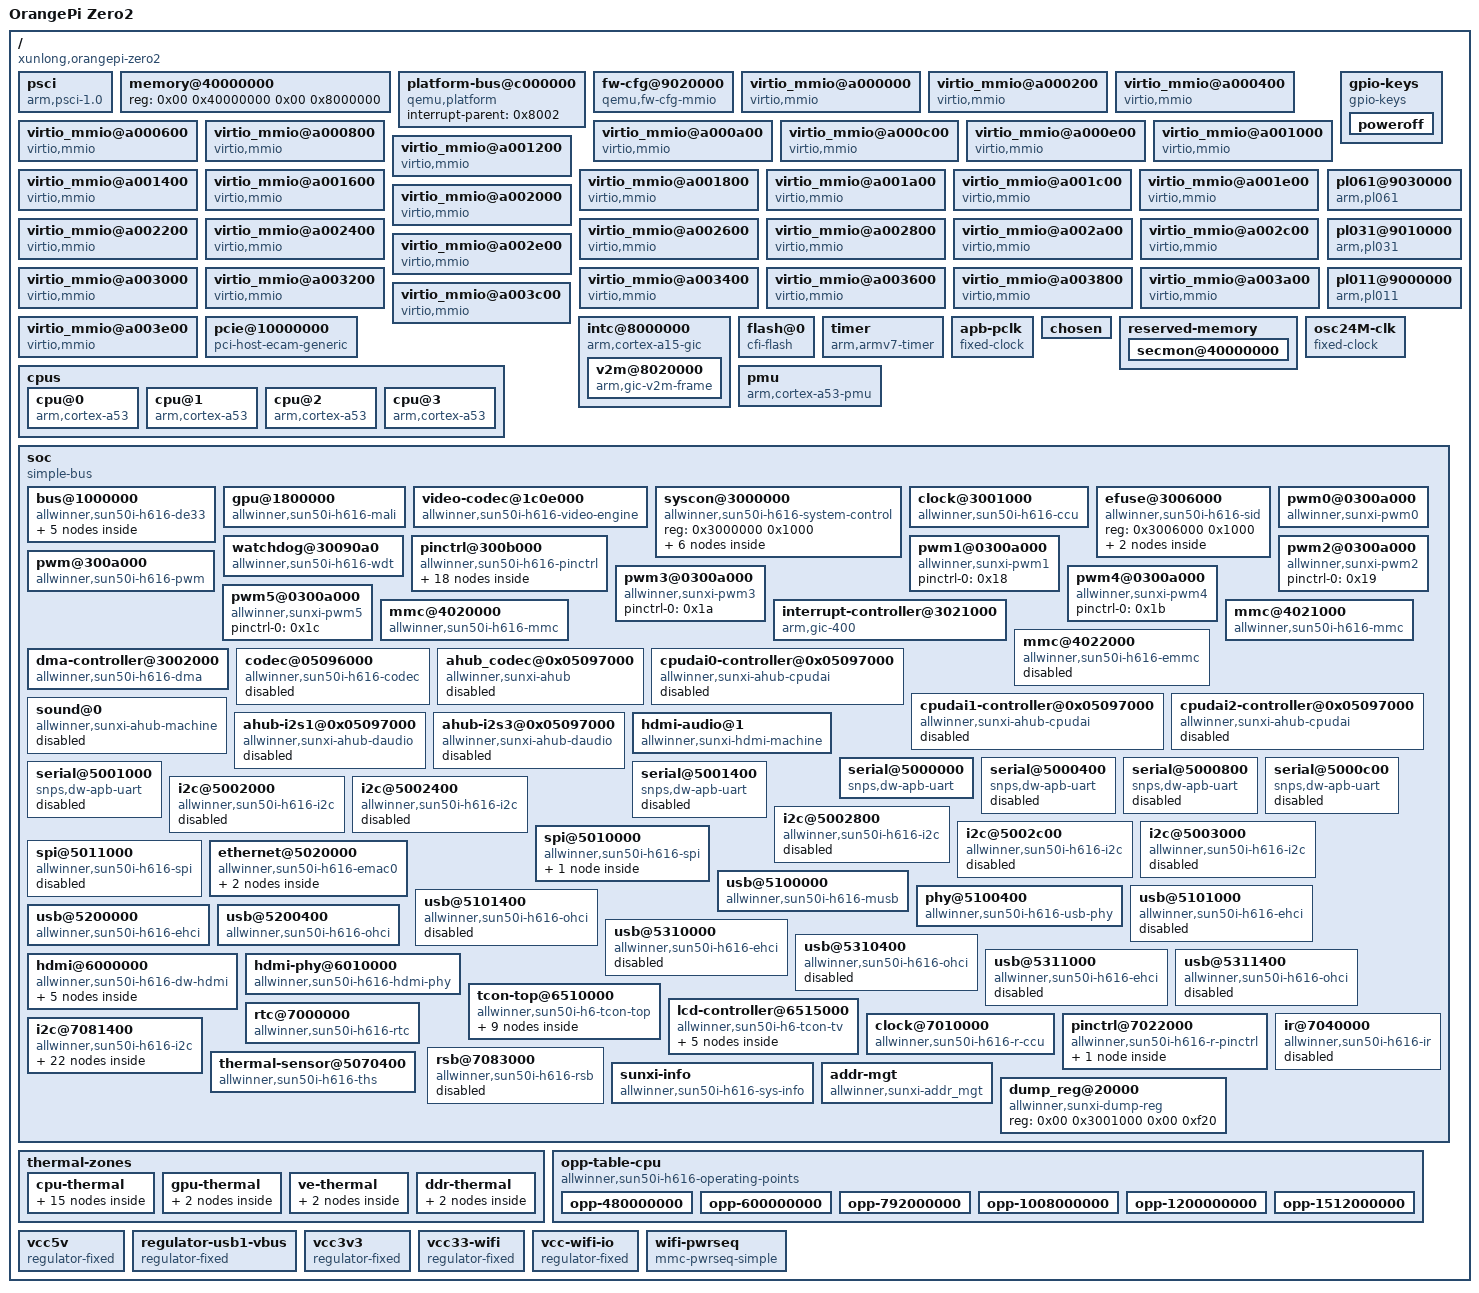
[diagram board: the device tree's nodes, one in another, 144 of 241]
/dts-v1/;

/ {
	#size-cells = <0x02>;
	#address-cells = <0x02>;

	model = "OrangePi Zero2";
	compatible = "xunlong,orangepi-zero2\0allwinner,sun50i-h616";

// qemu specific
	interrupt-parent = <0x8002>;

	psci {
		migrate = <0x84000005>;
		cpu_on = <0x84000003>;
		cpu_off = <0x84000002>;
		cpu_suspend = <0x84000001>;
		method = "hvc";
		compatible = "arm,psci-1.0\0arm,psci-0.2\0arm,psci";
	};

	memory@40000000 {
		reg = <0x00 0x40000000 0x00 0x8000000>;
		device_type = "memory";
	};

	platform-bus@c000000 {
		interrupt-parent = <0x8002>;
		ranges = <0x00 0x00 0xc000000 0x2000000>;
		#address-cells = <0x01>;
		#size-cells = <0x01>;
		compatible = "qemu,platform\0simple-bus";
	};

	fw-cfg@9020000 {
		dma-coherent;
		reg = <0x00 0x9020000 0x00 0x18>;
		compatible = "qemu,fw-cfg-mmio";
	};

	virtio_mmio@a000000 {
		dma-coherent;
		interrupts = <0x00 0x10 0x01>;
		reg = <0x00 0xa000000 0x00 0x200>;
		compatible = "virtio,mmio";
	};

	virtio_mmio@a000200 {
		dma-coherent;
		interrupts = <0x00 0x11 0x01>;
		reg = <0x00 0xa000200 0x00 0x200>;
		compatible = "virtio,mmio";
	};

	virtio_mmio@a000400 {
		dma-coherent;
		interrupts = <0x00 0x12 0x01>;
		reg = <0x00 0xa000400 0x00 0x200>;
		compatible = "virtio,mmio";
	};

	virtio_mmio@a000600 {
		dma-coherent;
		interrupts = <0x00 0x13 0x01>;
		reg = <0x00 0xa000600 0x00 0x200>;
		compatible = "virtio,mmio";
	};

	virtio_mmio@a000800 {
		dma-coherent;
		interrupts = <0x00 0x14 0x01>;
		reg = <0x00 0xa000800 0x00 0x200>;
		compatible = "virtio,mmio";
	};

	virtio_mmio@a000a00 {
		dma-coherent;
		interrupts = <0x00 0x15 0x01>;
		reg = <0x00 0xa000a00 0x00 0x200>;
		compatible = "virtio,mmio";
	};

	virtio_mmio@a000c00 {
		dma-coherent;
		interrupts = <0x00 0x16 0x01>;
		reg = <0x00 0xa000c00 0x00 0x200>;
		compatible = "virtio,mmio";
	};

	virtio_mmio@a000e00 {
		dma-coherent;
		interrupts = <0x00 0x17 0x01>;
		reg = <0x00 0xa000e00 0x00 0x200>;
		compatible = "virtio,mmio";
	};

	virtio_mmio@a001000 {
		dma-coherent;
		interrupts = <0x00 0x18 0x01>;
		reg = <0x00 0xa001000 0x00 0x200>;
		compatible = "virtio,mmio";
	};

	virtio_mmio@a001200 {
		dma-coherent;
		interrupts = <0x00 0x19 0x01>;
		reg = <0x00 0xa001200 0x00 0x200>;
		compatible = "virtio,mmio";
	};

	virtio_mmio@a001400 {
		dma-coherent;
		interrupts = <0x00 0x1a 0x01>;
		reg = <0x00 0xa001400 0x00 0x200>;
		compatible = "virtio,mmio";
	};

	virtio_mmio@a001600 {
		dma-coherent;
		interrupts = <0x00 0x1b 0x01>;
		reg = <0x00 0xa001600 0x00 0x200>;
		compatible = "virtio,mmio";
	};

	virtio_mmio@a001800 {
		dma-coherent;
		interrupts = <0x00 0x1c 0x01>;
		reg = <0x00 0xa001800 0x00 0x200>;
		compatible = "virtio,mmio";
	};

	virtio_mmio@a001a00 {
		dma-coherent;
		interrupts = <0x00 0x1d 0x01>;
		reg = <0x00 0xa001a00 0x00 0x200>;
		compatible = "virtio,mmio";
	};

	virtio_mmio@a001c00 {
		dma-coherent;
		interrupts = <0x00 0x1e 0x01>;
		reg = <0x00 0xa001c00 0x00 0x200>;
		compatible = "virtio,mmio";
	};

	virtio_mmio@a001e00 {
		dma-coherent;
		interrupts = <0x00 0x1f 0x01>;
		reg = <0x00 0xa001e00 0x00 0x200>;
		compatible = "virtio,mmio";
	};

	virtio_mmio@a002000 {
		dma-coherent;
		interrupts = <0x00 0x20 0x01>;
		reg = <0x00 0xa002000 0x00 0x200>;
		compatible = "virtio,mmio";
	};

	virtio_mmio@a002200 {
		dma-coherent;
		interrupts = <0x00 0x21 0x01>;
		reg = <0x00 0xa002200 0x00 0x200>;
		compatible = "virtio,mmio";
	};

	virtio_mmio@a002400 {
		dma-coherent;
		interrupts = <0x00 0x22 0x01>;
		reg = <0x00 0xa002400 0x00 0x200>;
		compatible = "virtio,mmio";
	};

	virtio_mmio@a002600 {
		dma-coherent;
		interrupts = <0x00 0x23 0x01>;
		reg = <0x00 0xa002600 0x00 0x200>;
		compatible = "virtio,mmio";
	};

	virtio_mmio@a002800 {
		dma-coherent;
		interrupts = <0x00 0x24 0x01>;
		reg = <0x00 0xa002800 0x00 0x200>;
		compatible = "virtio,mmio";
	};

	virtio_mmio@a002a00 {
		dma-coherent;
		interrupts = <0x00 0x25 0x01>;
		reg = <0x00 0xa002a00 0x00 0x200>;
		compatible = "virtio,mmio";
	};

	virtio_mmio@a002c00 {
		dma-coherent;
		interrupts = <0x00 0x26 0x01>;
		reg = <0x00 0xa002c00 0x00 0x200>;
		compatible = "virtio,mmio";
	};

	virtio_mmio@a002e00 {
		dma-coherent;
		interrupts = <0x00 0x27 0x01>;
		reg = <0x00 0xa002e00 0x00 0x200>;
		compatible = "virtio,mmio";
	};

	virtio_mmio@a003000 {
		dma-coherent;
		interrupts = <0x00 0x28 0x01>;
		reg = <0x00 0xa003000 0x00 0x200>;
		compatible = "virtio,mmio";
	};

	virtio_mmio@a003200 {
		dma-coherent;
		interrupts = <0x00 0x29 0x01>;
		reg = <0x00 0xa003200 0x00 0x200>;
		compatible = "virtio,mmio";
	};

	virtio_mmio@a003400 {
		dma-coherent;
		interrupts = <0x00 0x2a 0x01>;
		reg = <0x00 0xa003400 0x00 0x200>;
		compatible = "virtio,mmio";
	};

	virtio_mmio@a003600 {
		dma-coherent;
		interrupts = <0x00 0x2b 0x01>;
		reg = <0x00 0xa003600 0x00 0x200>;
		compatible = "virtio,mmio";
	};

	virtio_mmio@a003800 {
		dma-coherent;
		interrupts = <0x00 0x2c 0x01>;
		reg = <0x00 0xa003800 0x00 0x200>;
		compatible = "virtio,mmio";
	};

	virtio_mmio@a003a00 {
		dma-coherent;
		interrupts = <0x00 0x2d 0x01>;
		reg = <0x00 0xa003a00 0x00 0x200>;
		compatible = "virtio,mmio";
	};

	virtio_mmio@a003c00 {
		dma-coherent;
		interrupts = <0x00 0x2e 0x01>;
		reg = <0x00 0xa003c00 0x00 0x200>;
		compatible = "virtio,mmio";
	};

	virtio_mmio@a003e00 {
		dma-coherent;
		interrupts = <0x00 0x2f 0x01>;
		reg = <0x00 0xa003e00 0x00 0x200>;
		compatible = "virtio,mmio";
	};

	gpio-keys {
		compatible = "gpio-keys";

		poweroff {
			gpios = <0x8004 0x03 0x00>;
			linux,code = <0x74>;
			label = "GPIO Key Poweroff";
		};
	};

	pl061@9030000 {
		phandle = <0x8004>;
		clock-names = "apb_pclk";
		clocks = <0x8000>;
		interrupts = <0x00 0x07 0x04>;
		gpio-controller;
		#gpio-cells = <0x02>;
		compatible = "arm,pl061\0arm,primecell";
		reg = <0x00 0x9030000 0x00 0x1000>;
	};

	pcie@10000000 {
		interrupt-map-mask = <0x1800 0x00 0x00 0x07>;
		interrupt-map = <0x00 0x00 0x00 0x01 0x8002 0x00 0x00 0x00 0x03 0x04 0x00 0x00 0x00 0x02 0x8002 0x00 0x00 0x00 0x04 0x04 0x00 0x00 0x00 0x03 0x8002 0x00 0x00 0x00 0x05 0x04 0x00 0x00 0x00 0x04 0x8002 0x00 0x00 0x00 0x06 0x04 0x800 0x00 0x00 0x01 0x8002 0x00 0x00 0x00 0x04 0x04 0x800 0x00 0x00 0x02 0x8002 0x00 0x00 0x00 0x05 0x04 0x800 0x00 0x00 0x03 0x8002 0x00 0x00 0x00 0x06 0x04 0x800 0x00 0x00 0x04 0x8002 0x00 0x00 0x00 0x03 0x04 0x1000 0x00 0x00 0x01 0x8002 0x00 0x00 0x00 0x05 0x04 0x1000 0x00 0x00 0x02 0x8002 0x00 0x00 0x00 0x06 0x04 0x1000 0x00 0x00 0x03 0x8002 0x00 0x00 0x00 0x03 0x04 0x1000 0x00 0x00 0x04 0x8002 0x00 0x00 0x00 0x04 0x04 0x1800 0x00 0x00 0x01 0x8002 0x00 0x00 0x00 0x06 0x04 0x1800 0x00 0x00 0x02 0x8002 0x00 0x00 0x00 0x03 0x04 0x1800 0x00 0x00 0x03 0x8002 0x00 0x00 0x00 0x04 0x04 0x1800 0x00 0x00 0x04 0x8002 0x00 0x00 0x00 0x05 0x04>;
		#interrupt-cells = <0x01>;
		ranges = <0x1000000 0x00 0x00 0x00 0x3eff0000 0x00 0x10000 0x2000000 0x00 0x10000000 0x00 0x10000000 0x00 0x2eff0000 0x3000000 0x80 0x00 0x80 0x00 0x80 0x00>;
		reg = <0x40 0x10000000 0x00 0x10000000>;
		msi-map = <0x00 0x8003 0x00 0x10000>;
		dma-coherent;
		bus-range = <0x00 0xff>;
		linux,pci-domain = <0x00>;
		#size-cells = <0x02>;
		#address-cells = <0x03>;
		device_type = "pci";
		compatible = "pci-host-ecam-generic";
	};

	pl031@9010000 {
		clock-names = "apb_pclk";
		clocks = <0x8000>;
		interrupts = <0x00 0x02 0x04>;
		reg = <0x00 0x9010000 0x00 0x1000>;
		compatible = "arm,pl031\0arm,primecell";
	};

	pl011@9000000 {
		clock-names = "uartclk\0apb_pclk";
		clocks = <0x8000 0x8000>;
		interrupts = <0x00 0x01 0x04>;
		reg = <0x00 0x9000000 0x00 0x1000>;
		compatible = "arm,pl011\0arm,primecell";
	};

	intc@8000000 {
		phandle = <0x8002>;
		reg = <0x00 0x8000000 0x00 0x10000 0x00 0x8010000 0x00 0x10000>;
		compatible = "arm,cortex-a15-gic";
		ranges;
		#size-cells = <0x02>;
		#address-cells = <0x02>;
		interrupt-controller;
		#interrupt-cells = <0x03>;

		v2m@8020000 {
			phandle = <0x8003>;
			reg = <0x00 0x8020000 0x00 0x1000>;
			msi-controller;
			compatible = "arm,gic-v2m-frame";
		};
	};

	flash@0 {
		bank-width = <0x04>;
		reg = <0x00 0x00 0x00 0x4000000 0x00 0x4000000 0x00 0x4000000>;
		compatible = "cfi-flash";
	};

	timer {
		interrupts = <0x01 0x0d 0x104 0x01 0x0e 0x104 0x01 0x0b 0x104 0x01 0x0a 0x104>;
		always-on;
		compatible = "arm,armv7-timer";
	};

	apb-pclk {
		phandle = <0x8000>;
		clock-output-names = "clk24mhz";
		clock-frequency = <0x16e3600>;
		#clock-cells = <0x00>;
		compatible = "fixed-clock";
	};

	chosen {
		stdout-path = "/pl011@9000000";
		rng-seed = <0x58b677a3 0xe02614cc 0xa6764dbf 0xe48418cb 0xdfab91ec 0x764a72a3 0x2a94ac82 0x8e271614>;
		kaslr-seed = <0x5f29de73 0xe7f581f>;
	};

// mangopi specific
	cpus {
		#address-cells = <0x01>;
		#size-cells = <0x00>;

		cpu@0 {
			compatible = "arm,cortex-a53";
			device_type = "cpu";
			reg = <0x00>;
			enable-method = "psci";
			clocks = <0x02 0x15>;
			clock-latency-ns = <0x3b9b0>;
			#cooling-cells = <0x02>;
			operating-points-v2 = <0x03>;
			cpu-supply = <0x04>;
			phandle = <0x06>;
		};

		cpu@1 {
			compatible = "arm,cortex-a53";
			device_type = "cpu";
			reg = <0x01>;
			enable-method = "psci";
			clocks = <0x02 0x15>;
			clock-latency-ns = <0x3b9b0>;
			#cooling-cells = <0x02>;
			operating-points-v2 = <0x03>;
			phandle = <0x07>;
		};

		cpu@2 {
			compatible = "arm,cortex-a53";
			device_type = "cpu";
			reg = <0x02>;
			enable-method = "psci";
			clocks = <0x02 0x15>;
			clock-latency-ns = <0x3b9b0>;
			#cooling-cells = <0x02>;
			operating-points-v2 = <0x03>;
			phandle = <0x08>;
		};

		cpu@3 {
			compatible = "arm,cortex-a53";
			device_type = "cpu";
			reg = <0x03>;
			enable-method = "psci";
			clocks = <0x02 0x15>;
			clock-latency-ns = <0x3b9b0>;
			#cooling-cells = <0x02>;
			operating-points-v2 = <0x03>;
			phandle = <0x09>;
		};
	};

	reserved-memory {
		#address-cells = <0x02>;
		#size-cells = <0x02>;
		ranges;

		secmon@40000000 {
			reg = <0x00 0x40000000 0x00 0x80000>;
			no-map;
		};
	};

	osc24M-clk {
		#clock-cells = <0x00>;
		compatible = "fixed-clock";
		clock-frequency = <0x16e3600>;
		clock-output-names = "osc24M";
		phandle = <0x0f>;
	};

	pmu {
		compatible = "arm,cortex-a53-pmu";
		interrupts = <0x00 0x8c 0x04 0x00 0x8d 0x04 0x00 0x8e 0x04 0x00 0x8f 0x04>;
		interrupt-affinity = <0x06 0x07 0x08 0x09>;
	};

	soc {
		compatible = "simple-bus";
		#address-cells = <0x01>;
		#size-cells = <0x01>;
		ranges = <0x00 0x00 0x00 0x40000000>;

		bus@1000000 {
			compatible = "allwinner,sun50i-h616-de33\0allwinner,sun50i-a64-de2";
			reg = <0x1000000 0x400000>;
			allwinner,sram = <0x0a 0x01>;
			#address-cells = <0x01>;
			#size-cells = <0x01>;
			ranges = <0x00 0x1000000 0x400000>;

			clock@8000 {
				compatible = "allwinner,sun50i-h616-de33-clk";
				reg = <0x8000 0x100>;
				clocks = <0x02 0x1d 0x02 0x1e>;
				clock-names = "mod\0bus";
				resets = <0x02 0x01>;
				#clock-cells = <0x01>;
				#reset-cells = <0x01>;
				phandle = <0x0b>;
			};

			mixer@100000 {
				compatible = "allwinner,sun50i-h616-de33-mixer-0";
				reg = <0x100000 0x100000 0x8100 0x40 0x280000 0x20000>;
				clocks = <0x0b 0x00 0x0b 0x06>;
				clock-names = "bus\0mod";
				resets = <0x0b 0x00>;
				phandle = <0x05>;

				ports {
					#address-cells = <0x01>;
					#size-cells = <0x00>;

					port@1 {
						reg = <0x01>;
						phandle = <0x4e>;

						endpoint {
							remote-endpoint = <0x0c>;
							phandle = <0x3a>;
						};
					};
				};
			};
		};

		gpu@1800000 {
			compatible = "allwinner,sun50i-h616-mali\0arm,mali-bifrost";
			reg = <0x1800000 0x40000>;
			interrupts = <0x00 0x5f 0x04 0x00 0x60 0x04 0x00 0x61 0x04>;
			interrupt-names = "job\0mmu\0gpu";
			clocks = <0x02 0x23 0x02 0x24>;
			clock-names = "core\0bus";
			resets = <0x02 0x03>;
			status = "okay";
			phy-supply = <0x0d>;
			phandle = <0x4f>;
		};

		video-codec@1c0e000 {
			compatible = "allwinner,sun50i-h616-video-engine";
			reg = <0x1c0e000 0x2000>;
			clocks = <0x02 0x29 0x02 0x28 0x02 0x33>;
			clock-names = "ahb\0mod\0ram";
			resets = <0x02 0x05>;
			interrupts = <0x00 0x5d 0x04>;
			allwinner,sram = <0x0e 0x01>;
		};

		syscon@3000000 {
			compatible = "allwinner,sun50i-h616-system-control";
			reg = <0x3000000 0x1000>;
			#address-cells = <0x01>;
			#size-cells = <0x01>;
			ranges;
			phandle = <0x30>;

			sram@100000 {
				compatible = "mmio-sram";
				reg = <0x100000 0x18000>;
				#address-cells = <0x01>;
				#size-cells = <0x01>;
				ranges = <0x00 0x100000 0x18000>;
				phandle = <0x50>;

				scpi-sram@17c00 {
					compatible = "arm,scp-shmem";
					reg = <0x17c00 0x200>;
					phandle = <0x51>;
				};
			};

			sram@28000 {
				compatible = "mmio-sram";
				reg = <0x28000 0x30000>;
				#address-cells = <0x01>;
				#size-cells = <0x01>;
				ranges = <0x00 0x28000 0x30000>;
				phandle = <0x52>;

				sram-section@0 {
					compatible = "allwinner,sun50i-h616-sram-c1\0allwinner,sun50i-a64-sram-c";
					reg = <0x00 0x1e000>;
					phandle = <0x0a>;
				};
			};

			sram@1a00000 {
				compatible = "mmio-sram";
				reg = <0x1a00000 0x200000>;
				#address-cells = <0x01>;
				#size-cells = <0x01>;
				ranges = <0x00 0x1a00000 0x200000>;
				phandle = <0x53>;

				sram-section@0 {
					compatible = "allwinner,sun50i-h616-sram-c1";
					reg = <0x00 0x200000>;
					phandle = <0x0e>;
				};
			};
		};

		clock@3001000 {
			compatible = "allwinner,sun50i-h616-ccu";
			reg = <0x3001000 0x1000>;
			clocks = <0x0f 0x10 0x00 0x10 0x02>;
			clock-names = "hosc\0losc\0iosc";
			#clock-cells = <0x01>;
			#reset-cells = <0x01>;
			phandle = <0x02>;
		};

		efuse@3006000 {
			compatible = "allwinner,sun50i-h616-sid";
			reg = <0x3006000 0x1000>;
			#address-cells = <0x01>;
			#size-cells = <0x01>;
			phandle = <0x54>;

			cpu-speed-grade@00 {
				reg = <0x00 0x02>;
				phandle = <0x55>;
			};

			thermal-sensor-calibration@14 {
				reg = <0x14 0x08>;
				phandle = <0x44>;
			};
		};

		watchdog@30090a0 {
			compatible = "allwinner,sun50i-h616-wdt\0allwinner,sun6i-a31-wdt";
			reg = <0x30090a0 0x20>;
			interrupts = <0x00 0x32 0x04>;
			clocks = <0x0f>;
			phandle = <0x56>;
		};

		pinctrl@300b000 {
			compatible = "allwinner,sun50i-h616-pinctrl";
			reg = <0x300b000 0x400>;
			interrupts = <0x00 0x33 0x04 0x00 0x34 0x04 0x00 0x35 0x04 0x00 0x2b 0x04 0x00 0x36 0x04 0x00 0x37 0x04 0x00 0x38 0x04 0x00 0x39 0x04>;
			clocks = <0x02 0x1a 0x0f 0x10 0x00>;
			clock-names = "apb\0hosc\0losc";
			gpio-controller;
			#gpio-cells = <0x03>;
			interrupt-controller;
			#interrupt-cells = <0x03>;
			vcc-pc-supply = <0x11>;
			vcc-pf-supply = <0x11>;
			vcc-pg-supply = <0x11>;
			vcc-ph-supply = <0x11>;
			vcc-pi-supply = <0x11>;
			phandle = <0x1e>;

			rgmii-pins {
				pins = "PI0\0PI1\0PI2\0PI3\0PI4\0PI5\0PI7\0PI8\0PI9\0PI10\0PI11\0PI12\0PI13\0PI14\0PI15\0PI16";
				function = "emac0";
				drive-strength = <0x28>;
				phandle = <0x31>;
			};

			i2c0-pins {
				pins = "PI6\0PI7";
				function = "i2c0";
				phandle = <0x2c>;
			};

			i2c3-ph-pins {
				pins = "PH4\0PH5";
				function = "i2c3";
				phandle = <0x57>;
			};

			i2c4-pins {
				pins = "PH6\0PH7";
				function = "i2c4";
				phandle = <0x58>;
			};

			i2s3-pins {
				pins = "PH5\0PH6\0PH7\0PH8\0PH9";
				function = "i2s3";
				phandle = <0x29>;
			};

			ir-rx-pin {
				pins = "PH10";
				function = "ir_rx";
				phandle = <0x42>;
			};

			pwm1-pin {
				pins = "PH3";
				function = "pwm1";
				phandle = <0x18>;
			};

			pwm2-pin {
				pins = "PH2";
				function = "pwm2";
				phandle = <0x19>;
			};

			pwm3-pin {
				pins = "PH0";
				function = "pwm3";
				phandle = <0x1a>;
			};

			pwm4-pin {
				pins = "PH1";
				function = "pwm4";
				phandle = <0x1b>;
			};

			pwm5-pin {
				pins = "PA12";
				function = "pwm5";
				phandle = <0x1c>;
			};

			mmc0-pins {
				pins = "PF0\0PF1\0PF2\0PF3\0PF4\0PF5";
				function = "mmc0";
				drive-strength = <0x1e>;
				bias-pull-up;
				phandle = <0x1d>;
			};

			mmc1-pins {
				pins = "PG0\0PG1\0PG2\0PG3\0PG4\0PG5";
				function = "mmc1";
				drive-strength = <0x1e>;
				bias-pull-up;
				phandle = <0x1f>;
			};

			mmc2-pins {
				pins = "PC0\0PC1\0PC5\0PC6\0PC8\0PC9\0PC10\0PC11\0PC13\0PC14\0PC15\0PC16";
				function = "mmc2";
				drive-strength = <0x1e>;
				bias-pull-up;
				phandle = <0x23>;
			};

			spi0-pins {
				pins = "PC0\0PC2\0PC4";
				function = "spi0";
				phandle = <0x2d>;
			};

			spi0-cs0-pin {
				pins = "PC3";
				function = "spi0";
				phandle = <0x2e>;
			};

			spi1-pins {
				pins = "PH6\0PH7\0PH8";
				function = "spi1";
				phandle = <0x2f>;
			};

			uart0-ph-pins {
				pins = "PH0\0PH1";
				function = "uart0";
				phandle = <0x2b>;
			};
		};

		pwm@300a000 {
			compatible = "allwinner,sun50i-h616-pwm";
			reg = <0x300a000 0x400>;
			clocks = <0x0f 0x02 0x2f>;
			clock-names = "mod\0bus";
			resets = <0x02 0x0a>;
			pwm-number = <0x06>;
			pwm-base = <0x00>;
			sunxi-pwms = <0x12 0x13 0x14 0x15 0x16 0x17>;
			#pwm-cells = <0x03>;
			status = "okay";
			phandle = <0x59>;
		};

		pwm0@0300a000 {
			compatible = "allwinner,sunxi-pwm0";
			phandle = <0x12>;
		};

		pwm1@0300a000 {
			compatible = "allwinner,sunxi-pwm1";
			pinctrl-names = "default";
			pinctrl-0 = <0x18>;
			phandle = <0x13>;
		};

		pwm2@0300a000 {
			compatible = "allwinner,sunxi-pwm2";
			pinctrl-names = "default";
			pinctrl-0 = <0x19>;
			phandle = <0x14>;
		};

		pwm3@0300a000 {
			compatible = "allwinner,sunxi-pwm3";
			pinctrl-names = "default";
			pinctrl-0 = <0x1a>;
			phandle = <0x15>;
		};

		pwm4@0300a000 {
			compatible = "allwinner,sunxi-pwm4";
			pinctrl-names = "default";
			pinctrl-0 = <0x1b>;
			phandle = <0x16>;
		};

		pwm5@0300a000 {
			compatible = "allwinner,sunxi-pwm5";
			pinctrl-names = "default";
			pinctrl-0 = <0x1c>;
			phandle = <0x17>;
		};

		interrupt-controller@3021000 {
			compatible = "arm,gic-400";
			reg = <0x3021000 0x1000 0x3022000 0x2000 0x3024000 0x2000 0x3026000 0x2000>;
			interrupts = <0x01 0x09 0xf04>;
			interrupt-controller;
			#interrupt-cells = <0x03>;
			phandle = <0x01>;
		};

		mmc@4020000 {
			compatible = "allwinner,sun50i-h616-mmc\0allwinner,sun50i-a100-mmc";
			reg = <0x4020000 0x1000>;
			clocks = <0x02 0x3f 0x02 0x3c>;
			clock-names = "ahb\0mmc";
			resets = <0x02 0x0e>;
			reset-names = "ahb";
			interrupts = <0x00 0x23 0x04>;
			pinctrl-names = "default";
			pinctrl-0 = <0x1d>;
			status = "okay";
			max-frequency = <0x8f0d180>;
			cap-sd-highspeed;
			cap-mmc-highspeed;
			mmc-ddr-3_3v;
			cap-sdio-irq;
			#address-cells = <0x01>;
			#size-cells = <0x00>;
			vmmc-supply = <0x11>;
			cd-gpios = <0x1e 0x05 0x06 0x01>;
			bus-width = <0x04>;
			phandle = <0x5a>;
		};

		mmc@4021000 {
			compatible = "allwinner,sun50i-h616-mmc\0allwinner,sun50i-a100-mmc";
			reg = <0x4021000 0x1000>;
			clocks = <0x02 0x40 0x02 0x3d>;
			clock-names = "ahb\0mmc";
			resets = <0x02 0x0f>;
			reset-names = "ahb";
			interrupts = <0x00 0x24 0x04>;
			pinctrl-names = "default";
			pinctrl-0 = <0x1f>;
			status = "okay";
			max-frequency = <0x8f0d180>;
			cap-sd-highspeed;
			cap-mmc-highspeed;
			mmc-ddr-3_3v;
			cap-sdio-irq;
			#address-cells = <0x01>;
			#size-cells = <0x00>;
			vmmc-supply = <0x20>;
			vqmmc-supply = <0x21>;
			mmc-pwrseq = <0x22>;
			bus-width = <0x04>;
			non-removable;
			mmc-ddr-1_8v;
			phandle = <0x5b>;
		};

		mmc@4022000 {
			compatible = "allwinner,sun50i-h616-emmc\0allwinner,sun50i-a100-emmc";
			reg = <0x4022000 0x1000>;
			clocks = <0x02 0x41 0x02 0x3e>;
			clock-names = "ahb\0mmc";
			resets = <0x02 0x10>;
			reset-names = "ahb";
			interrupts = <0x00 0x25 0x04>;
			pinctrl-names = "default";
			pinctrl-0 = <0x23>;
			status = "disabled";
			max-frequency = <0x8f0d180>;
			cap-sd-highspeed;
			cap-mmc-highspeed;
			mmc-ddr-3_3v;
			cap-sdio-irq;
			#address-cells = <0x01>;
			#size-cells = <0x00>;
			phandle = <0x5c>;
		};

		dma-controller@3002000 {
			compatible = "allwinner,sun50i-h616-dma";
			reg = <0x3002000 0x1000>;
			interrupts = <0x00 0x2a 0x04>;
			clocks = <0x02 0x2a 0x02 0x32>;
			clock-names = "bus\0mbus";
			dma-channels = <0x10>;
			dma-requests = <0x31>;
			resets = <0x02 0x06>;
			#dma-cells = <0x01>;
			phandle = <0x24>;
		};

		codec@05096000 {
			#sound-dai-cells = <0x00>;
			compatible = "allwinner,sun50i-h616-codec";
			reg = <0x5096000 0x31c>;
			interrupts = <0x00 0x3a 0x04>;
			clocks = <0x02 0x5d 0x02 0x5b 0x02 0x5c>;
			clock-names = "apb\0audio-codec-1x\0audio-codec-4x";
			resets = <0x02 0x24>;
			dmas = <0x24 0x06>;
			dma-names = "tx";
			status = "disabled";
			phandle = <0x5d>;
		};

		ahub_codec@0x05097000 {
			compatible = "allwinner,sunxi-ahub";
			reg = <0x5097000 0xadf>;
			clocks = <0x02 0x5f 0x02 0x5b 0x02 0x5c 0x02 0x5e>;
			clock-names = "apb\0audio-codec-1x\0audio-codec-4x\0audio-hub";
			resets = <0x02 0x25>;
			status = "disabled";
			phandle = <0x28>;
		};

		cpudai0-controller@0x05097000 {
			compatible = "allwinner,sunxi-ahub-cpudai";
			reg = <0x5097000 0xadf>;
			id = <0x00>;
			dmas = <0x24 0x03 0x24 0x03>;
			dma-names = "rx\0tx";
			status = "disabled";
			phandle = <0x25>;
		};

		cpudai1-controller@0x05097000 {
			compatible = "allwinner,sunxi-ahub-cpudai";
			reg = <0x5097000 0xadf>;
			id = <0x01>;
			dmas = <0x24 0x04 0x24 0x04>;
			dma-names = "rx\0tx";
			status = "disabled";
			phandle = <0x26>;
		};

		cpudai2-controller@0x05097000 {
			compatible = "allwinner,sunxi-ahub-cpudai";
			reg = <0x5097000 0xadf>;
			id = <0x02>;
			dmas = <0x24 0x05 0x24 0x05>;
			dma-names = "rx\0tx";
			status = "disabled";
			phandle = <0x27>;
		};

		sound@0 {
			compatible = "allwinner,sunxi-ahub-machine";
			sunxi,cpudai-controller0 = <0x25>;
			sunxi,cpudai-controller1 = <0x26>;
			sunxi,cpudai-controller2 = <0x27>;
			sunxi,audio-codec = <0x28>;
			status = "disabled";
			phandle = <0x5e>;
		};

		ahub-i2s1@0x05097000 {
			#sound-dai-cells = <0x00>;
			compatible = "allwinner,sunxi-ahub-daudio";
			reg = <0x5097000 0xadf>;
			clocks = <0x02 0x5f 0x02 0x5b 0x02 0x5c 0x02 0x5e>;
			clock-names = "apb\0audio-codec-1x\0audio-codec-4x\0audio-hub";
			tdm_num = <0x01>;
			pinconfig = <0x00>;
			frametype = <0x00>;
			pcm_lrck_period = <0x20>;
			slot_width_select = <0x20>;
			daudio_master = <0x04>;
			audio_format = <0x01>;
			signal_inversion = <0x01>;
			tdm_config = <0x01>;
			mclk_div = <0x01>;
			status = "disabled";
			phandle = <0x2a>;
		};

		ahub-i2s3@0x05097000 {
			compatible = "allwinner,sunxi-ahub-daudio";
			reg = <0x5097000 0xadf>;
			clocks = <0x02 0x5f 0x02 0x5b 0x02 0x5c 0x02 0x5e>;
			clock-names = "apb\0audio-codec-1x\0audio-codec-4x\0audio-hub";
			pinctrl-names = "default";
			pinctrl-0 = <0x29>;
			tdm_num = <0x03>;
			pinconfig = <0x01>;
			frametype = <0x00>;
			pcm_lrck_period = <0x20>;
			slot_width_select = <0x20>;
			daudio_master = <0x04>;
			audio_format = <0x01>;
			signal_inversion = <0x01>;
			tdm_config = <0x01>;
			mclk_div = <0x04>;
			status = "disabled";
			phandle = <0x5f>;
		};

		hdmi-audio@1 {
			compatible = "allwinner,sunxi-hdmi-machine";
			sunxi,cpudai-controller = <0x2a>;
			sunxi,snddaudio-codec = "hdmi-audio-codec.4.auto";
			status = "okay";
			phandle = <0x60>;
		};

		serial@5000000 {
			compatible = "snps,dw-apb-uart";
			reg = <0x5000000 0x400>;
			interrupts = <0x00 0x00 0x04>;
			reg-shift = <0x02>;
			reg-io-width = <0x04>;
			clocks = <0x02 0x42>;
			resets = <0x02 0x11>;
			status = "okay";
			pinctrl-names = "default";
			pinctrl-0 = <0x2b>;
			phandle = <0x61>;
		};

		serial@5000400 {
			compatible = "snps,dw-apb-uart";
			reg = <0x5000400 0x400>;
			interrupts = <0x00 0x01 0x04>;
			reg-shift = <0x02>;
			reg-io-width = <0x04>;
			clocks = <0x02 0x43>;
			resets = <0x02 0x12>;
			status = "disabled";
			phandle = <0x62>;
		};

		serial@5000800 {
			compatible = "snps,dw-apb-uart";
			reg = <0x5000800 0x400>;
			interrupts = <0x00 0x02 0x04>;
			reg-shift = <0x02>;
			reg-io-width = <0x04>;
			clocks = <0x02 0x44>;
			resets = <0x02 0x13>;
			status = "disabled";
			phandle = <0x63>;
		};

		serial@5000c00 {
			compatible = "snps,dw-apb-uart";
			reg = <0x5000c00 0x400>;
			interrupts = <0x00 0x03 0x04>;
			reg-shift = <0x02>;
			reg-io-width = <0x04>;
			clocks = <0x02 0x45>;
			resets = <0x02 0x14>;
			status = "disabled";
			phandle = <0x64>;
		};

		serial@5001000 {
			compatible = "snps,dw-apb-uart";
			reg = <0x5001000 0x400>;
			interrupts = <0x00 0x04 0x04>;
			reg-shift = <0x02>;
			reg-io-width = <0x04>;
			clocks = <0x02 0x46>;
			resets = <0x02 0x15>;
			status = "disabled";
			phandle = <0x65>;
		};

		serial@5001400 {
			compatible = "snps,dw-apb-uart";
			reg = <0x5001400 0x400>;
			interrupts = <0x00 0x05 0x04>;
			reg-shift = <0x02>;
			reg-io-width = <0x04>;
			clocks = <0x02 0x47>;
			resets = <0x02 0x16>;
			status = "disabled";
			phandle = <0x66>;
		};

		i2c@5002000 {
			compatible = "allwinner,sun50i-h616-i2c\0allwinner,sun8i-v536-i2c\0allwinner,sun6i-a31-i2c";
			reg = <0x5002000 0x400>;
			interrupts = <0x00 0x06 0x04>;
			clocks = <0x02 0x48>;
			resets = <0x02 0x17>;
			pinctrl-names = "default";
			pinctrl-0 = <0x2c>;
			status = "disabled";
			#address-cells = <0x01>;
			#size-cells = <0x00>;
			phandle = <0x67>;
		};

		i2c@5002400 {
			compatible = "allwinner,sun50i-h616-i2c\0allwinner,sun8i-v536-i2c\0allwinner,sun6i-a31-i2c";
			reg = <0x5002400 0x400>;
			interrupts = <0x00 0x07 0x04>;
			clocks = <0x02 0x49>;
			resets = <0x02 0x18>;
			status = "disabled";
			#address-cells = <0x01>;
			#size-cells = <0x00>;
			phandle = <0x68>;
		};

		i2c@5002800 {
			compatible = "allwinner,sun50i-h616-i2c\0allwinner,sun8i-v536-i2c\0allwinner,sun6i-a31-i2c";
			reg = <0x5002800 0x400>;
			interrupts = <0x00 0x08 0x04>;
			clocks = <0x02 0x4a>;
			resets = <0x02 0x19>;
			status = "disabled";
			#address-cells = <0x01>;
			#size-cells = <0x00>;
			phandle = <0x69>;
		};

		i2c@5002c00 {
			compatible = "allwinner,sun50i-h616-i2c\0allwinner,sun8i-v536-i2c\0allwinner,sun6i-a31-i2c";
			reg = <0x5002c00 0x400>;
			interrupts = <0x00 0x09 0x04>;
			clocks = <0x02 0x4b>;
			resets = <0x02 0x1a>;
			status = "disabled";
			#address-cells = <0x01>;
			#size-cells = <0x00>;
			phandle = <0x6a>;
		};

		i2c@5003000 {
			compatible = "allwinner,sun50i-h616-i2c\0allwinner,sun8i-v536-i2c\0allwinner,sun6i-a31-i2c";
			reg = <0x5003000 0x400>;
			interrupts = <0x00 0x0a 0x04>;
			clocks = <0x02 0x4c>;
			resets = <0x02 0x1b>;
			status = "disabled";
			#address-cells = <0x01>;
			#size-cells = <0x00>;
			phandle = <0x6b>;
		};

		spi@5010000 {
			compatible = "allwinner,sun50i-h616-spi\0allwinner,sun8i-h3-spi";
			reg = <0x5010000 0x1000>;
			interrupts = <0x00 0x0c 0x04>;
			clocks = <0x02 0x4f 0x02 0x4d>;
			clock-names = "ahb\0mod";
			resets = <0x02 0x1c>;
			pinctrl-names = "default";
			pinctrl-0 = <0x2d 0x2e>;
			status = "okay";
			#address-cells = <0x01>;
			#size-cells = <0x00>;
			phandle = <0x6c>;

			flash@0 {
				#address-cells = <0x01>;
				#size-cells = <0x01>;
				compatible = "jedec,spi-nor";
				reg = <0x00>;
				spi-max-frequency = <0x2625a00>;
			};
		};

		spi@5011000 {
			compatible = "allwinner,sun50i-h616-spi\0allwinner,sun8i-h3-spi";
			reg = <0x5011000 0x1000>;
			interrupts = <0x00 0x0d 0x04>;
			clocks = <0x02 0x50 0x02 0x4e>;
			clock-names = "ahb\0mod";
			resets = <0x02 0x1d>;
			pinctrl-names = "default";
			pinctrl-0 = <0x2f>;
			status = "disabled";
			#address-cells = <0x01>;
			#size-cells = <0x00>;
			phandle = <0x6d>;
		};

		ethernet@5020000 {
			compatible = "allwinner,sun50i-h616-emac0\0allwinner,sun50i-a64-emac";
			reg = <0x5020000 0x10000>;
			interrupts = <0x00 0x0e 0x04>;
			interrupt-names = "macirq";
			clocks = <0x02 0x52>;
			clock-names = "stmmaceth";
			resets = <0x02 0x1e>;
			reset-names = "stmmaceth";
			syscon = <0x30>;
			status = "okay";
			pinctrl-names = "default";
			pinctrl-0 = <0x31>;
			phy-mode = "rgmii";
			phy-handle = <0x32>;
			phy-supply = <0x33>;
			allwinner,rx-delay-ps = <0xc1c>;
			allwinner,tx-delay-ps = <0x2bc>;
			phandle = <0x6e>;

			mdio {
				compatible = "snps,dwmac-mdio";
				#address-cells = <0x01>;
				#size-cells = <0x00>;
				phandle = <0x6f>;

				ethernet-phy@1 {
					compatible = "ethernet-phy-ieee802.3-c22";
					reg = <0x01>;
					phandle = <0x32>;
				};
			};
		};

		usb@5100000 {
			compatible = "allwinner,sun50i-h616-musb\0allwinner,sun8i-h3-musb";
			reg = <0x5100000 0x400>;
			clocks = <0x02 0x70>;
			resets = <0x02 0x32>;
			interrupts = <0x00 0x19 0x04>;
			interrupt-names = "mc";
			phys = <0x34 0x00>;
			phy-names = "usb";
			extcon = <0x34 0x00>;
			status = "okay";
			dr_mode = "peripheral";
			phandle = <0x70>;
		};

		phy@5100400 {
			compatible = "allwinner,sun50i-h616-usb-phy";
			reg = <0x5100400 0x24 0x5101800 0x14 0x5200800 0x14 0x5310800 0x14 0x5311800 0x14>;
			reg-names = "phy_ctrl\0pmu0\0pmu1\0pmu2\0pmu3";
			clocks = <0x02 0x61 0x02 0x63 0x02 0x65 0x02 0x67 0x02 0x6e>;
			clock-names = "usb0_phy\0usb1_phy\0usb2_phy\0usb3_phy\0pmu2_clk";
			resets = <0x02 0x26 0x02 0x27 0x02 0x28 0x02 0x29>;
			reset-names = "usb0_reset\0usb1_reset\0usb2_reset\0usb3_reset";
			status = "okay";
			#phy-cells = <0x01>;
			usb1_vbus-supply = <0x35>;
			phandle = <0x34>;
		};

		usb@5101000 {
			compatible = "allwinner,sun50i-h616-ehci\0generic-ehci";
			reg = <0x5101000 0x100>;
			interrupts = <0x00 0x1a 0x04>;
			clocks = <0x02 0x68 0x02 0x6c 0x02 0x60>;
			resets = <0x02 0x2a 0x02 0x2e>;
			phys = <0x34 0x00>;
			phy-names = "usb";
			status = "disabled";
			phandle = <0x71>;
		};

		usb@5101400 {
			compatible = "allwinner,sun50i-h616-ohci\0generic-ohci";
			reg = <0x5101400 0x100>;
			interrupts = <0x00 0x1b 0x04>;
			clocks = <0x02 0x68 0x02 0x60>;
			resets = <0x02 0x2a>;
			phys = <0x34 0x00>;
			phy-names = "usb";
			status = "disabled";
			phandle = <0x72>;
		};

		usb@5200000 {
			compatible = "allwinner,sun50i-h616-ehci\0generic-ehci";
			reg = <0x5200000 0x100>;
			interrupts = <0x00 0x1c 0x04>;
			clocks = <0x02 0x69 0x02 0x6d 0x02 0x62>;
			resets = <0x02 0x2b 0x02 0x2f>;
			phys = <0x34 0x01>;
			phy-names = "usb";
			status = "okay";
			phandle = <0x73>;
		};

		usb@5200400 {
			compatible = "allwinner,sun50i-h616-ohci\0generic-ohci";
			reg = <0x5200400 0x100>;
			interrupts = <0x00 0x1d 0x04>;
			clocks = <0x02 0x69 0x02 0x62>;
			resets = <0x02 0x2b>;
			phys = <0x34 0x01>;
			phy-names = "usb";
			status = "okay";
			phandle = <0x74>;
		};

		usb@5310000 {
			compatible = "allwinner,sun50i-h616-ehci\0generic-ehci";
			reg = <0x5310000 0x100>;
			interrupts = <0x00 0x1e 0x04>;
			clocks = <0x02 0x6a 0x02 0x6e 0x02 0x64>;
			resets = <0x02 0x2c 0x02 0x30>;
			phys = <0x34 0x02>;
			phy-names = "usb";
			status = "disabled";
			phandle = <0x75>;
		};

		usb@5310400 {
			compatible = "allwinner,sun50i-h616-ohci\0generic-ohci";
			reg = <0x5310400 0x100>;
			interrupts = <0x00 0x1f 0x04>;
			clocks = <0x02 0x6a 0x02 0x64>;
			resets = <0x02 0x2c>;
			phys = <0x34 0x02>;
			phy-names = "usb";
			status = "disabled";
			phandle = <0x76>;
		};

		usb@5311000 {
			compatible = "allwinner,sun50i-h616-ehci\0generic-ehci";
			reg = <0x5311000 0x100>;
			interrupts = <0x00 0x20 0x04>;
			clocks = <0x02 0x6b 0x02 0x6f 0x02 0x66>;
			resets = <0x02 0x2d 0x02 0x31>;
			phys = <0x34 0x03>;
			phy-names = "usb";
			status = "disabled";
			phandle = <0x77>;
		};

		usb@5311400 {
			compatible = "allwinner,sun50i-h616-ohci\0generic-ohci";
			reg = <0x5311400 0x100>;
			interrupts = <0x00 0x21 0x04>;
			clocks = <0x02 0x6b 0x02 0x66>;
			resets = <0x02 0x2d>;
			phys = <0x34 0x03>;
			phy-names = "usb";
			status = "disabled";
			phandle = <0x78>;
		};

		hdmi@6000000 {
			compatible = "allwinner,sun50i-h616-dw-hdmi\0allwinner,sun50i-h6-dw-hdmi";
			reg = <0x6000000 0x10000>;
			reg-io-width = <0x01>;
			interrupts = <0x00 0x3f 0x04>;
			clocks = <0x02 0x75 0x02 0x73 0x02 0x72 0x02 0x74 0x02 0x7e 0x02 0x7f>;
			clock-names = "iahb\0isfr\0tmds\0cec\0hdcp\0hdcp-bus";
			resets = <0x02 0x33 0x02 0x3a>;
			reset-names = "ctrl\0hdcp";
			phys = <0x36>;
			phy-names = "phy";
			status = "okay";
			hvcc-supply = <0x37>;
			phandle = <0x79>;

			ports {
				#address-cells = <0x01>;
				#size-cells = <0x00>;

				port@0 {
					reg = <0x00>;
					phandle = <0x7a>;

					endpoint {
						remote-endpoint = <0x38>;
						phandle = <0x3d>;
					};
				};

				port@1 {
					reg = <0x01>;
					phandle = <0x7b>;

					endpoint {
						remote-endpoint = <0x39>;
						phandle = <0x4b>;
					};
				};
			};
		};

		hdmi-phy@6010000 {
			compatible = "allwinner,sun50i-h616-hdmi-phy";
			reg = <0x6010000 0x10000>;
			clocks = <0x02 0x75 0x02 0x73>;
			clock-names = "bus\0mod";
			resets = <0x02 0x34>;
			reset-names = "phy";
			#phy-cells = <0x00>;
			phandle = <0x36>;
		};

		tcon-top@6510000 {
			compatible = "allwinner,sun50i-h6-tcon-top";
			reg = <0x6510000 0x1000>;
			clocks = <0x02 0x76 0x02 0x77>;
			clock-names = "bus\0tcon-tv0";
			clock-output-names = "tcon-top-tv0";
			resets = <0x02 0x35>;
			#clock-cells = <0x01>;
			phandle = <0x3e>;

			ports {
				#address-cells = <0x01>;
				#size-cells = <0x00>;

				port@0 {
					#address-cells = <0x01>;
					#size-cells = <0x00>;
					reg = <0x00>;
					phandle = <0x7c>;

					endpoint@0 {
						reg = <0x00>;
						remote-endpoint = <0x3a>;
						phandle = <0x0c>;
					};
				};

				port@1 {
					#address-cells = <0x01>;
					#size-cells = <0x00>;
					reg = <0x01>;
					phandle = <0x7d>;

					endpoint@2 {
						reg = <0x02>;
						remote-endpoint = <0x3b>;
						phandle = <0x3f>;
					};
				};

				port@4 {
					#address-cells = <0x01>;
					#size-cells = <0x00>;
					reg = <0x04>;
					phandle = <0x7e>;

					endpoint@0 {
						reg = <0x00>;
						remote-endpoint = <0x3c>;
						phandle = <0x40>;
					};
				};

				port@5 {
					reg = <0x05>;
					phandle = <0x7f>;

					endpoint {
						remote-endpoint = <0x3d>;
						phandle = <0x38>;
					};
				};
			};
		};

		lcd-controller@6515000 {
			compatible = "allwinner,sun50i-h6-tcon-tv\0allwinner,sun8i-r40-tcon-tv";
			reg = <0x6515000 0x1000>;
			interrupts = <0x00 0x42 0x04>;
			clocks = <0x02 0x79 0x3e 0x00>;
			clock-names = "ahb\0tcon-ch1";
			resets = <0x02 0x36>;
			reset-names = "lcd";
			phandle = <0x80>;

			ports {
				#address-cells = <0x01>;
				#size-cells = <0x00>;

				port@0 {
					reg = <0x00>;
					phandle = <0x81>;

					endpoint {
						remote-endpoint = <0x3f>;
						phandle = <0x3b>;
					};
				};

				port@1 {
					#address-cells = <0x01>;
					#size-cells = <0x00>;
					reg = <0x01>;
					phandle = <0x82>;

					endpoint@1 {
						reg = <0x01>;
						remote-endpoint = <0x40>;
						phandle = <0x3c>;
					};
				};
			};
		};

		rtc@7000000 {
			compatible = "allwinner,sun50i-h616-rtc";
			reg = <0x7000000 0x400>;
			interrupts = <0x00 0x68 0x04>;
			clocks = <0x41 0x0e 0x0f 0x02 0x80>;
			clock-names = "bus\0hosc\0pll-32k";
			#clock-cells = <0x01>;
			phandle = <0x10>;
		};

		clock@7010000 {
			compatible = "allwinner,sun50i-h616-r-ccu";
			reg = <0x7010000 0x210>;
			clocks = <0x0f 0x10 0x00 0x10 0x02 0x02 0x04>;
			clock-names = "hosc\0losc\0iosc\0pll-periph";
			#clock-cells = <0x01>;
			#reset-cells = <0x01>;
			phandle = <0x41>;
		};

		pinctrl@7022000 {
			compatible = "allwinner,sun50i-h616-r-pinctrl";
			interrupts = <0x00 0x2b 0x04>;
			reg = <0x7022000 0x400>;
			clocks = <0x41 0x02 0x0f 0x10 0x00>;
			clock-names = "apb\0hosc\0losc";
			gpio-controller;
			#gpio-cells = <0x03>;
			interrupt-controller;
			#interrupt-cells = <0x03>;
			phandle = <0x83>;

			r-rsb-pins {
				pins = "PL0\0PL1";
				function = "s_rsb";
				phandle = <0x43>;
			};
		};

		ir@7040000 {
			compatible = "allwinner,sun50i-h616-ir\0allwinner,sun6i-a31-ir";
			reg = <0x7040000 0x400>;
			interrupts = <0x00 0x6a 0x04>;
			clocks = <0x41 0x09 0x41 0x0b>;
			clock-names = "apb\0ir";
			resets = <0x41 0x05>;
			pinctrl-names = "default";
			pinctrl-0 = <0x42>;
			status = "disabled";
			phandle = <0x84>;
		};

		i2c@7081400 {
			compatible = "allwinner,sun50i-h616-i2c\0allwinner,sun8i-v536-i2c\0allwinner,sun6i-a31-i2c";
			reg = <0x7081400 0x400>;
			interrupts = <0x00 0x69 0x04>;
			clocks = <0x41 0x08>;
			resets = <0x41 0x04>;
			status = "okay";
			#address-cells = <0x01>;
			#size-cells = <0x00>;
			phandle = <0x85>;

			pmic@36 {
				compatible = "x-powers,axp1530";
				status = "okay";
				reg = <0x36>;
				wakeup-source;
				phandle = <0x86>;

				standby_param {
					vcc-dram = <0x04>;
					phandle = <0x87>;
				};

				regulators {

					dcdca {
						regulator-always-on;
						regulator-min-microvolt = <0xc5c10>;
						regulator-max-microvolt = <0x10c8e0>;
						regulator-name = "vdd-cpu";
						phandle = <0x04>;
					};

					dcdcc {
						regulator-always-on;
						regulator-min-microvolt = <0xc5c10>;
						regulator-max-microvolt = <0xf1b30>;
						regulator-name = "vdd-gpu-sys";
						phandle = <0x0d>;
					};

					dcdcd {
						regulator-always-on;
						regulator-min-microvolt = <0x16e360>;
						regulator-max-microvolt = <0x16e360>;
						regulator-name = "vdd-dram";
						phandle = <0x88>;
					};

					dcdce {
						regulator-always-on;
						regulator-min-microvolt = <0x325aa0>;
						regulator-max-microvolt = <0x325aa0>;
						regulator-name = "vcc-eth-mmc";
						phandle = <0x33>;
					};

					dcdc1 {
						regulator-name = "axp1530-dcdc1";
						regulator-min-microvolt = <0x7a120>;
						regulator-max-microvolt = <0x33e140>;
						regulator-step-delay-us = <0x19>;
						regulator-final-delay-us = <0x32>;
						regulator-always-on;
						phandle = <0x89>;
					};

					dcdc2 {
						regulator-name = "axp1530-dcdc2";
						regulator-min-microvolt = <0x7a120>;
						regulator-max-microvolt = <0x177fa0>;
						regulator-step-delay-us = <0x19>;
						regulator-final-delay-us = <0x32>;
						regulator-ramp-delay = <0xc8>;
						regulator-always-on;
						phandle = <0x8a>;
					};

					dcdc3 {
						regulator-name = "axp1530-dcdc3";
						regulator-min-microvolt = <0x7a120>;
						regulator-max-microvolt = <0x1c1380>;
						regulator-step-delay-us = <0x19>;
						regulator-final-delay-us = <0x32>;
						regulator-always-on;
						phandle = <0x8b>;
					};

					dldo1 {
						regulator-name = "axp1530-dldo1";
						regulator-min-microvolt = <0x325aa0>;
						regulator-max-microvolt = <0x325aa0>;
						regulator-step-delay-us = <0x19>;
						regulator-final-delay-us = <0x32>;
						regulator-always-on;
						phandle = <0x8c>;
					};

					aldo1 {
						regulator-always-on;
						regulator-min-microvolt = <0x325aa0>;
						regulator-max-microvolt = <0x325aa0>;
						regulator-name = "vcc-sys";
						phandle = <0x8d>;
					};

					aldo2 {
						regulator-always-on;
						regulator-min-microvolt = <0x325aa0>;
						regulator-max-microvolt = <0x325aa0>;
						regulator-name = "vcc3v3-ext";
						phandle = <0x8e>;
					};

					aldo3 {
						regulator-always-on;
						regulator-min-microvolt = <0x325aa0>;
						regulator-max-microvolt = <0x325aa0>;
						regulator-name = "vcc3v3-ext2";
						phandle = <0x8f>;
					};

					bldo1 {
						regulator-always-on;
						regulator-min-microvolt = <0x1b7740>;
						regulator-max-microvolt = <0x1b7740>;
						regulator-name = "vcc1v8";
						phandle = <0x37>;
					};

					bldo2 {
						regulator-always-on;
						regulator-min-microvolt = <0x1b7740>;
						regulator-max-microvolt = <0x1b7740>;
						regulator-name = "vcc1v8";
						phandle = <0x90>;
					};

					bldo3 {
					};

					bldo4 {
					};

					cldo1 {
					};

					cldo2 {
					};

					cldo3 {
					};

					sw {
					};
				};
			};
		};

		rsb@7083000 {
			compatible = "allwinner,sun50i-h616-rsb\0allwinner,sun8i-a23-rsb";
			reg = <0x7083000 0x400>;
			interrupts = <0x00 0x6d 0x04>;
			clocks = <0x41 0x0d>;
			clock-frequency = <0x2dc6c0>;
			resets = <0x41 0x07>;
			pinctrl-names = "default";
			pinctrl-0 = <0x43>;
			status = "disabled";
			#address-cells = <0x01>;
			#size-cells = <0x00>;
			phandle = <0x91>;
		};

		thermal-sensor@5070400 {
			compatible = "allwinner,sun50i-h616-ths";
			reg = <0x5070400 0x400>;
			interrupts = <0x00 0x13 0x04>;
			clocks = <0x02 0x56>;
			clock-names = "bus";
			resets = <0x02 0x21>;
			nvmem-cells = <0x44>;
			nvmem-cell-names = "calibration";
			#thermal-sensor-cells = <0x01>;
			phandle = <0x45>;
		};

		sunxi-info {
			compatible = "allwinner,sun50i-h616-sys-info";
			status = "okay";
		};

		addr-mgt {
			compatible = "allwinner,sunxi-addr_mgt";
			type_addr_wifi = <0x02>;
			type_addr_bt = <0x02>;
			type_addr_eth = <0x02>;
			status = "okay";
			phandle = <0x92>;
		};

		dump_reg@20000 {
			compatible = "allwinner,sunxi-dump-reg";
			reg = <0x00 0x3001000 0x00 0xf20>;
			status = "okay";
			phandle = <0x93>;
		};
	};

	thermal-zones {

		cpu-thermal {
			polling-delay-passive = <0x1f4>;
			polling-delay = <0x3e8>;
			thermal-sensors = <0x45 0x02>;
			sustainable-power = <0x3e8>;
			k_po = <0x14>;
			k_pu = <0x28>;
			k_i = <0x00>;

			trips {

				trip-point@0 {
					temperature = <0xea60>;
					type = "passive";
					hysteresis = <0x00>;
					phandle = <0x94>;
				};

				trip-point@1 {
					temperature = <0x11170>;
					type = "passive";
					hysteresis = <0x00>;
					phandle = <0x95>;
				};

				cpu_warm {
					temperature = <0x124f8>;
					hysteresis = <0x7d0>;
					type = "passive";
					phandle = <0x46>;
				};

				cpu_hot_pre {
					temperature = <0x13880>;
					hysteresis = <0x7d0>;
					type = "passive";
					phandle = <0x47>;
				};

				cpu_hot {
					temperature = <0x14c08>;
					hysteresis = <0x7d0>;
					type = "passive";
					phandle = <0x48>;
				};

				cpu_very_hot_pre {
					temperature = <0x15f90>;
					hysteresis = <0x7d0>;
					type = "passive";
					phandle = <0x49>;
				};

				cpu_very_hot {
					temperature = <0x17318>;
					hysteresis = <0x7d0>;
					type = "passive";
					phandle = <0x4a>;
				};

				cpu_crit {
					temperature = <0x19a28>;
					hysteresis = <0x7d0>;
					type = "critical";
					phandle = <0x96>;
				};
			};

			cooling-maps {

				cpu_warm_limit_cpu {
					trip = <0x46>;
					cooling-device = <0x06 0xffffffff 0x02>;
				};

				cpu_hot_pre_limit_cpu {
					trip = <0x47>;
					cooling-device = <0x06 0x02 0x03>;
				};

				cpu_hot_limit_cpu {
					trip = <0x48>;
					cooling-device = <0x06 0x03 0x04>;
				};

				cpu_very_hot_pre_limit_cpu {
					trip = <0x49>;
					cooling-device = <0x06 0x05 0x06>;
				};

				cpu_very_hot_limit_cpu {
					trip = <0x4a>;
					cooling-device = <0x06 0x07 0xffffffff>;
				};
			};
		};

		gpu-thermal {
			polling-delay-passive = <0x1f4>;
			polling-delay = <0x3e8>;
			thermal-sensors = <0x45 0x00>;
			sustainable-power = <0x44c>;

			trips {

				trip-point@0 {
					temperature = <0x1adb0>;
					type = "critical";
					hysteresis = <0x00>;
					phandle = <0x97>;
				};
			};
		};

		ve-thermal {
			polling-delay-passive = <0x00>;
			polling-delay = <0x00>;
			thermal-sensors = <0x45 0x01>;

			trips {

				trip-point@0 {
					temperature = <0x1adb0>;
					type = "critical";
					hysteresis = <0x00>;
					phandle = <0x98>;
				};
			};
		};

		ddr-thermal {
			polling-delay-passive = <0x00>;
			polling-delay = <0x00>;
			thermal-sensors = <0x45 0x03>;

			trips {

				trip-point@0 {
					temperature = <0x1adb0>;
					type = "critical";
					hysteresis = <0x00>;
					phandle = <0x99>;
				};
			};
		};
	};

	opp-table-cpu {
		compatible = "allwinner,sun50i-h616-operating-points";
		nvmem-cells = <0x55>;
		opp-shared;
		phandle = <0x03>;

		opp-480000000 {
			clock-latency-ns = <0x3b9b0>;
			opp-hz = <0x00 0x1c9c3800>;
			opp-microvolt-speed0 = <0xc8320 0xc8320 0x10c8e0>;
			opp-microvolt-speed1 = <0xd6d80 0xd6d80 0x10c8e0>;
			opp-microvolt-speed2 = <0xd6d80 0xd6d80 0x10c8e0>;
		};

		opp-600000000 {
			clock-latency-ns = <0x3b9b0>;
			opp-hz = <0x00 0x23c34600>;
			opp-microvolt-speed0 = <0xc8320 0xc8320 0x10c8e0>;
			opp-microvolt-speed1 = <0xd6d80 0xd6d80 0x10c8e0>;
			opp-microvolt-speed2 = <0xd6d80 0xd6d80 0x10c8e0>;
		};

		opp-792000000 {
			clock-latency-ns = <0x3b9b0>;
			opp-hz = <0x00 0x2f34f600>;
			opp-microvolt-speed0 = <0xd1f60 0xd1f60 0x10c8e0>;
			opp-microvolt-speed1 = <0xe57e0 0xe57e0 0x10c8e0>;
			opp-microvolt-speed2 = <0xe57e0 0xe57e0 0x10c8e0>;
		};

		opp-1008000000 {
			clock-latency-ns = <0x3b9b0>;
			opp-hz = <0x00 0x3c14dc00>;
			opp-microvolt-speed0 = <0xdbba0 0xdbba0 0x10c8e0>;
			opp-microvolt-speed1 = <0xf9060 0xf9060 0x10c8e0>;
			opp-microvolt-speed2 = <0xf9060 0xf9060 0x10c8e0>;
		};

		opp-1200000000 {
			clock-latency-ns = <0x3b9b0>;
			opp-hz = <0x00 0x47868c00>;
			opp-microvolt-speed0 = <0xea600 0xea600 0x10c8e0>;
			opp-microvolt-speed1 = <0x10c8e0 0x10c8e0 0x10c8e0>;
			opp-microvolt-speed2 = <0x10c8e0 0x10c8e0 0x10c8e0>;
		};

		opp-1512000000 {
			clock-latency-ns = <0x3b9b0>;
			opp-hz = <0x00 0x5a1f4a00>;
			opp-microvolt-speed0 = <0x10c8e0 0x10c8e0 0x10c8e0>;
			opp-microvolt-speed1 = <0x10c8e0 0x10c8e0 0x10c8e0>;
			opp-microvolt-speed2 = <0x10c8e0 0x10c8e0 0x10c8e0>;
		};
	};

	vcc5v {
		compatible = "regulator-fixed";
		regulator-name = "vcc-5v";
		regulator-min-microvolt = <0x4c4b40>;
		regulator-max-microvolt = <0x4c4b40>;
		regulator-always-on;
		phandle = <0x4c>;
	};

	regulator-usb1-vbus {
		compatible = "regulator-fixed";
		regulator-name = "usb1-vbus";
		regulator-min-microvolt = <0x4c4b40>;
		regulator-max-microvolt = <0x4c4b40>;
		vin-supply = <0x4c>;
		enable-active-high;
		gpio = <0x1e 0x02 0x10 0x00>;
		phandle = <0x35>;
	};

	vcc3v3 {
		compatible = "regulator-fixed";
		regulator-name = "vcc-3v3";
		regulator-min-microvolt = <0x325aa0>;
		regulator-max-microvolt = <0x325aa0>;
		regulator-always-on;
		phandle = <0x11>;
	};

	vcc33-wifi {
		compatible = "regulator-fixed";
		regulator-name = "vcc33-wifi";
		regulator-min-microvolt = <0x325aa0>;
		regulator-max-microvolt = <0x325aa0>;
		regulator-always-on;
		vin-supply = <0x4c>;
		phandle = <0x20>;
	};

	vcc-wifi-io {
		compatible = "regulator-fixed";
		regulator-name = "vcc-wifi-io";
		regulator-min-microvolt = <0x1b7740>;
		regulator-max-microvolt = <0x1b7740>;
		regulator-always-on;
		vin-supply = <0x20>;
		phandle = <0x21>;
	};

	wifi-pwrseq {
		compatible = "mmc-pwrseq-simple";
		clocks = <0x10 0x01>;
		clock-names = "osc32k-out";
		reset-gpios = <0x1e 0x06 0x12 0x01>;
		post-power-on-delay-ms = <0xc8>;
		phandle = <0x22>;
	};
};
